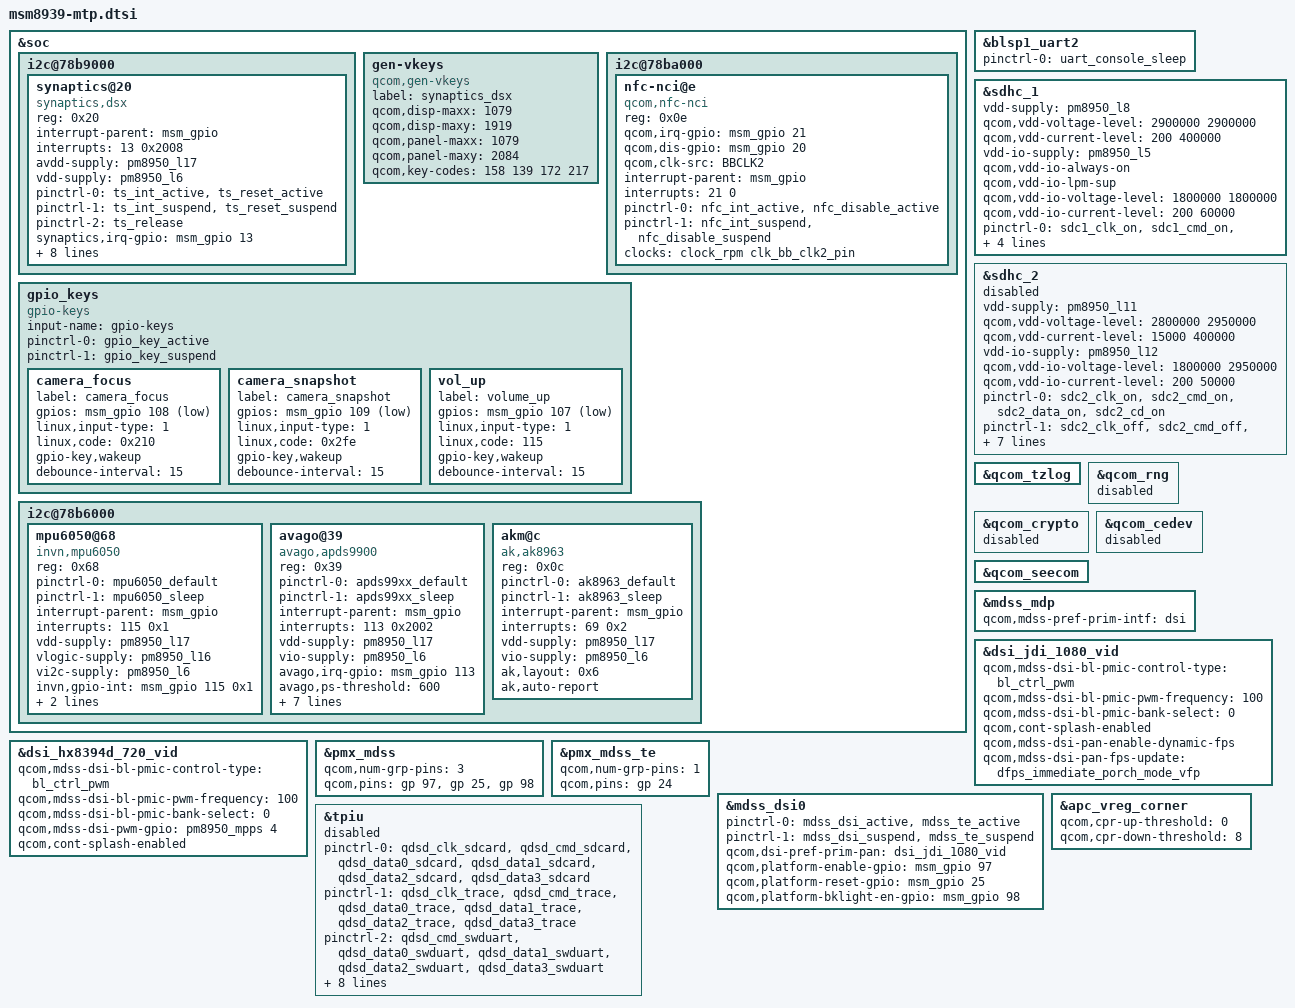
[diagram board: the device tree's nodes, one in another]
/*
 * Copyright (c) 2014-2015, The Linux Foundation. All rights reserved.
 *
 * This program is free software; you can redistribute it and/or modify
 * it under the terms of the GNU General Public License version 2 and
 * only version 2 as published by the Free Software Foundation.
 *
 * This program is distributed in the hope that it will be useful,
 * but WITHOUT ANY WARRANTY; without even the implied warranty of
 * MERCHANTABILITY or FITNESS FOR A PARTICULAR PURPOSE.  See the
 * GNU General Public License for more details.
 */

#include "msm8939-pinctrl.dtsi"

&soc {
	i2c@78b9000 { /* BLSP1 QUP5 */
		synaptics@20 {
			compatible = "synaptics,dsx";
			reg = <0x20>;
			interrupt-parent = <&msm_gpio>;
			interrupts = <13 0x2008>;
			avdd-supply = <&pm8950_l17>;
			vdd-supply = <&pm8950_l6>;
			/* pins used by touchscreen */
			pinctrl-names = "pmx_ts_active","pmx_ts_suspend","pmx_ts_suspend";
			pinctrl-0 = <&ts_int_active &ts_reset_active>;
			pinctrl-1 = <&ts_int_suspend &ts_reset_suspend>;
			pinctrl-2 = <&ts_release>;
			synaptics,irq-gpio = <&msm_gpio 13 0x2008>;
			synaptics,reset-gpio = <&msm_gpio 12 0x0>;
			synaptics,i2c-pull-up;
			synaptics,power-down;
			synaptics,disable-gpios;
			synaptics,display-coords = <0 0 1079 1919>;
			synaptics,panel-coords = <0 0 1079 2084>;
			/* Underlying clocks used by secure touch */
			clocks = <&clock_gcc clk_gcc_blsp1_ahb_clk>,
			 <&clock_gcc clk_gcc_blsp1_qup5_i2c_apps_clk>;
			clock-names = "iface_clk", "core_clk";
		};
	};

	gen-vkeys {
		compatible = "qcom,gen-vkeys";
		label = "synaptics_dsx";
		qcom,disp-maxx = <1079>;
		qcom,disp-maxy = <1919>;
		qcom,panel-maxx = <1079>;
		qcom,panel-maxy = <2084>;
		qcom,key-codes = <158 139 172 217>;
	};

	i2c@78ba000 { /* BLSP1 QUP6 */
		nfc-nci@e {
			compatible = "qcom,nfc-nci";
			reg = <0x0e>;
			qcom,irq-gpio = <&msm_gpio 21 0x00>;
			qcom,dis-gpio = <&msm_gpio 20 0x00>;
			qcom,clk-src = "BBCLK2";
			interrupt-parent = <&msm_gpio>;
			interrupts = <21 0>;
			interrupt-names = "nfc_irq";
			pinctrl-names = "nfc_active","nfc_suspend";
			pinctrl-0 = <&nfc_int_active &nfc_disable_active>;
			pinctrl-1 = <&nfc_int_suspend &nfc_disable_suspend>;
			/* Revisit: Removing PM8950 GPIOs */
			/* qcom,clk-gpio = <&pm8950_gpios 2 0>; */
			clocks = <&clock_rpm clk_bb_clk2_pin>;
			clock-names = "ref_clk";
		};
	};
	gpio_keys {
		compatible = "gpio-keys";
		input-name = "gpio-keys";
		pinctrl-names = "tlmm_gpio_key_active","tlmm_gpio_key_suspend";
		pinctrl-0 = <&gpio_key_active>;
		pinctrl-1 = <&gpio_key_suspend>;

		camera_focus {
			label = "camera_focus";
			gpios = <&msm_gpio 108 0x1>;
			linux,input-type = <1>;
			linux,code = <0x210>;
			gpio-key,wakeup;
			debounce-interval = <15>;
		};

		camera_snapshot {
			label = "camera_snapshot";
			gpios = <&msm_gpio 109 0x1>;
			linux,input-type = <1>;
			linux,code = <0x2fe>;
			gpio-key,wakeup;
			debounce-interval = <15>;
		};

		vol_up {
			label = "volume_up";
			gpios = <&msm_gpio 107 0x1>;
			linux,input-type = <1>;
			linux,code = <115>;
			gpio-key,wakeup;
			debounce-interval = <15>;
		};
	};

	i2c@78b6000 { /* BLSP1 QUP2 */
		mpu6050@68 { /* Gyroscope and accelerometer sensor combo */
			compatible = "invn,mpu6050";
			reg = <0x68>;
			pinctrl-names = "mpu_default","mpu_sleep";
			pinctrl-0 = <&mpu6050_default>;
			pinctrl-1 = <&mpu6050_sleep>;
			interrupt-parent = <&msm_gpio>;
			interrupts = <115 0x1>;
			vdd-supply = <&pm8950_l17>;
			vlogic-supply = <&pm8950_l16>;
			vi2c-supply = <&pm8950_l6>;
			invn,gpio-int = <&msm_gpio 115 0x1>;
			invn,place = "Portrait Down Back Side";
			invn,use-interrupt;
		};

		avago@39 { /* Ambient light and proximity sensor */
			compatible = "avago,apds9900";
			reg = <0x39>;
			pinctrl-names = "default","sleep";
			pinctrl-0 = <&apds99xx_default>;
			pinctrl-1 = <&apds99xx_sleep>;
			interrupt-parent = <&msm_gpio>;
			interrupts = <113 0x2002>;
			vdd-supply = <&pm8950_l17>;
			vio-supply = <&pm8950_l6>;
			avago,irq-gpio = <&msm_gpio 113 0x2002>;
			avago,ps-threshold = <600>;
			avago,ps-hysteresis-threshold = <500>;
			avago,ps-pulse = <8>;
			avago,ps-pgain = <0>;
			avago,als-B = <186>;
			avago,als-C = <75>;
			avago,als-D = <129>;
			avago,ga-value = <560>;
		};

		akm@c {
			compatible = "ak,ak8963";
			reg = <0x0c>;
			pinctrl-names = "ak8963_default", "ak8963_sleep";
			pinctrl-0 = <&ak8963_default>;
			pinctrl-1 = <&ak8963_sleep>;
			interrupt-parent = <&msm_gpio>;
			interrupts = <69 0x2>;
			vdd-supply = <&pm8950_l17>;
			vio-supply = <&pm8950_l6>;
			ak,layout = <0x6>;
			ak,auto-report;
		};

	};
};

&blsp1_uart2 {
	status = "ok";
	pinctrl-names = "default";
	pinctrl-0 = <&uart_console_sleep>;
};

&sdhc_1 {
	vdd-supply = <&pm8950_l8>;
	qcom,vdd-voltage-level = <2900000 2900000>;
	qcom,vdd-current-level = <200 400000>;

	vdd-io-supply = <&pm8950_l5>;
	qcom,vdd-io-always-on;
	qcom,vdd-io-lpm-sup;
	qcom,vdd-io-voltage-level = <1800000 1800000>;
	qcom,vdd-io-current-level = <200 60000>;

	pinctrl-names = "active", "sleep";
	pinctrl-0 = <&sdc1_clk_on &sdc1_cmd_on &sdc1_data_on>;
	pinctrl-1 = <&sdc1_clk_off &sdc1_cmd_off &sdc1_data_off>;

	qcom,nonremovable;

	status = "ok";
};

&sdhc_2 {
	vdd-supply = <&pm8950_l11>;
	qcom,vdd-voltage-level = <2800000 2950000>;
	qcom,vdd-current-level = <15000 400000>;

	vdd-io-supply = <&pm8950_l12>;
	qcom,vdd-io-voltage-level = <1800000 2950000>;
	qcom,vdd-io-current-level = <200 50000>;

	pinctrl-names = "active", "sleep";
	pinctrl-0 = <&sdc2_clk_on &sdc2_cmd_on &sdc2_data_on &sdc2_cd_on>;
	pinctrl-1 = <&sdc2_clk_off &sdc2_cmd_off &sdc2_data_off &sdc2_cd_off>;

	#address-cells = <0>;
	interrupt-parent = <&sdhc_2>;
	interrupts = <0 1 2>;
	#interrupt-cells = <1>;
	interrupt-map-mask = <0xffffffff>;
	interrupt-map = <0 &intc 0 125 0
			1 &intc 0 221 0
			2 &msm_gpio 38 0>;
	interrupt-names = "hc_irq", "pwr_irq", "status_irq";
	cd-gpios = <&msm_gpio 38 0x1>;

	status = "disabled";
};

&qcom_tzlog {
	status = "okay";
};

&qcom_rng {
	status = "disabled";
};

&qcom_crypto {
	status = "disabled";
};

&qcom_cedev {
	status = "disabled";
};

&qcom_seecom {
	status = "okay";
};

#include "dsi-panel-jdi-1080p-video.dtsi"
#include "dsi-panel-hx8394d-720p-video.dtsi"

&mdss_mdp {
	qcom,mdss-pref-prim-intf = "dsi";
};

&dsi_jdi_1080_vid {
	qcom,mdss-dsi-bl-pmic-control-type = "bl_ctrl_pwm";
	qcom,mdss-dsi-bl-pmic-pwm-frequency = <100>;
	qcom,mdss-dsi-bl-pmic-bank-select = <0>;
	// Revisit: Removing PM8950 MPP
	// qcom,mdss-dsi-pwm-gpio = <&pm8950_mpps 4 0>;
	qcom,cont-splash-enabled;
	qcom,mdss-dsi-pan-enable-dynamic-fps;
	qcom,mdss-dsi-pan-fps-update = "dfps_immediate_porch_mode_vfp";
};

&dsi_hx8394d_720_vid {
	qcom,mdss-dsi-bl-pmic-control-type = "bl_ctrl_pwm";
	qcom,mdss-dsi-bl-pmic-pwm-frequency = <100>;
	qcom,mdss-dsi-bl-pmic-bank-select = <0>;
	qcom,mdss-dsi-pwm-gpio = <&pm8950_mpps 4 0>;
	qcom,cont-splash-enabled;
};

&pmx_mdss {
	qcom,num-grp-pins = <3>;
	qcom,pins = <&gp 97>, <&gp 25>, <&gp 98>;
};

&pmx_mdss_te {
	qcom,num-grp-pins = <1>;
	qcom,pins = <&gp 24>;
};

&mdss_dsi0 {
	pinctrl-names = "mdss_default", "mdss_sleep";
	pinctrl-0 = <&mdss_dsi_active &mdss_te_active>;
	pinctrl-1 = <&mdss_dsi_suspend &mdss_te_suspend>;
	qcom,dsi-pref-prim-pan = <&dsi_jdi_1080_vid>;

	qcom,platform-enable-gpio = <&msm_gpio 97 0>;
	qcom,platform-reset-gpio = <&msm_gpio 25 0>;
	qcom,platform-bklight-en-gpio = <&msm_gpio 98 0>;
};

/* CoreSight */
&tpiu {
	status = "disabled";
	pinctrl-names = "sdcard", "trace", "swduart",
			"swdtrc", "jtag", "spmi";
	/* NIDnT */
	pinctrl-0 = <&qdsd_clk_sdcard &qdsd_cmd_sdcard
		     &qdsd_data0_sdcard &qdsd_data1_sdcard
		     &qdsd_data2_sdcard &qdsd_data3_sdcard>;
	pinctrl-1 = <&qdsd_clk_trace &qdsd_cmd_trace
		     &qdsd_data0_trace &qdsd_data1_trace
		     &qdsd_data2_trace &qdsd_data3_trace>;
	pinctrl-2 = <&qdsd_cmd_swduart &qdsd_data0_swduart
		     &qdsd_data1_swduart &qdsd_data2_swduart
		     &qdsd_data3_swduart>;
	pinctrl-3 = <&qdsd_clk_swdtrc &qdsd_cmd_swdtrc
		     &qdsd_data0_swdtrc &qdsd_data1_swdtrc
		     &qdsd_data2_swdtrc &qdsd_data3_swdtrc>;
	pinctrl-4 = <&qdsd_cmd_jtag &qdsd_data0_jtag
		     &qdsd_data1_jtag &qdsd_data2_jtag
		     &qdsd_data3_jtag>;
	pinctrl-5 = <&qdsd_clk_spmi &qdsd_cmd_spmi
		     &qdsd_data0_spmi &qdsd_data3_spmi>;
};

&apc_vreg_corner {
		qcom,cpr-up-threshold = <0>;
		qcom,cpr-down-threshold = <8>;
};
